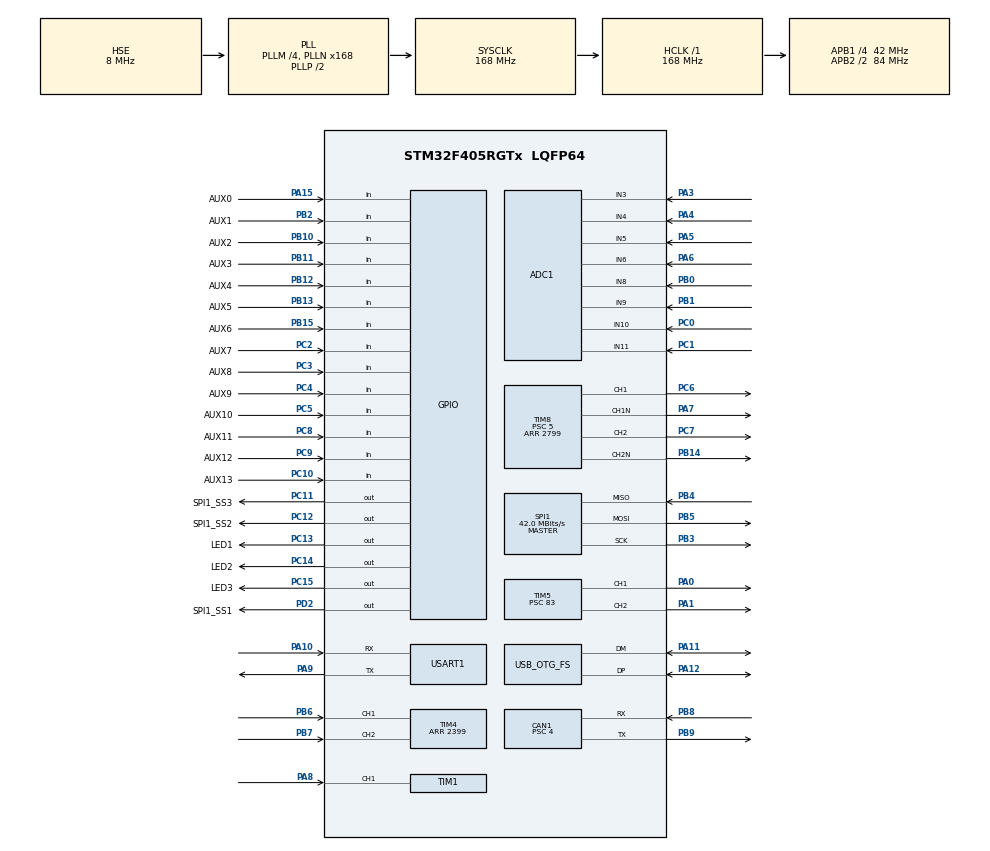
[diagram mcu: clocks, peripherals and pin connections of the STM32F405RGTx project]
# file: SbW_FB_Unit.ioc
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ADC1.Channel-0\#ChannelRegularConversion=ADC_CHANNEL_3
ADC1.Channel-10\#ChannelRegularConversion=ADC_CHANNEL_4
ADC1.Channel-3\#ChannelRegularConversion=ADC_CHANNEL_4
ADC1.Channel-4\#ChannelRegularConversion=ADC_CHANNEL_3
ADC1.Channel-5\#ChannelRegularConversion=ADC_CHANNEL_3
ADC1.Channel-6\#ChannelRegularConversion=ADC_CHANNEL_3
ADC1.Channel-7\#ChannelRegularConversion=ADC_CHANNEL_3
ADC1.Channel-8\#ChannelRegularConversion=ADC_CHANNEL_3
ADC1.Channel-9\#ChannelRegularConversion=ADC_CHANNEL_3
ADC1.DMAContinuousRequests=ENABLE
ADC1.EOCSelection=ADC_EOC_SEQ_CONV
ADC1.ExternalTrigConv=ADC_EXTERNALTRIGCONV_T5_CC2
ADC1.NbrOfConversion=9
ADC1.NbrOfConversionFlag=1
ADC1.Rank-0\#ChannelRegularConversion=1
ADC1.Rank-10\#ChannelRegularConversion=9
ADC1.Rank-3\#ChannelRegularConversion=2
ADC1.Rank-4\#ChannelRegularConversion=3
ADC1.Rank-5\#ChannelRegularConversion=4
ADC1.Rank-6\#ChannelRegularConversion=5
ADC1.Rank-7\#ChannelRegularConversion=6
ADC1.Rank-8\#ChannelRegularConversion=7
ADC1.Rank-9\#ChannelRegularConversion=8
ADC1.SamplingTime-0\#ChannelRegularConversion=ADC_SAMPLETIME_112CYCLES
ADC1.SamplingTime-10\#ChannelRegularConversion=ADC_SAMPLETIME_112CYCLES
ADC1.SamplingTime-3\#ChannelRegularConversion=ADC_SAMPLETIME_112CYCLES
ADC1.SamplingTime-4\#ChannelRegularConversion=ADC_SAMPLETIME_3CYCLES
ADC1.SamplingTime-5\#ChannelRegularConversion=ADC_SAMPLETIME_3CYCLES
ADC1.SamplingTime-6\#ChannelRegularConversion=ADC_SAMPLETIME_3CYCLES
ADC1.SamplingTime-7\#ChannelRegularConversion=ADC_SAMPLETIME_3CYCLES
ADC1.SamplingTime-8\#ChannelRegularConversion=ADC_SAMPLETIME_3CYCLES
ADC1.SamplingTime-9\#ChannelRegularConversion=ADC_SAMPLETIME_3CYCLES
ADC1.ScanConvMode=ENABLE
ADC1.master=1
CAN1.BS1=CAN_BS1_15TQ
CAN1.BS2=CAN_BS2_5TQ
CAN1.CalculateBaudRate=500000
CAN1.CalculateTimeBit=2000
CAN1.CalculateTimeQuantum=95.23809523809524
CAN1.Prescaler=4
Dma.ADC1.1.Direction=DMA_PERIPH_TO_MEMORY
Dma.ADC1.1.FIFOMode=DMA_FIFOMODE_DISABLE
Dma.ADC1.1.Instance=DMA2_Stream0
Dma.ADC1.1.MemDataAlignment=DMA_MDATAALIGN_HALFWORD
Dma.ADC1.1.MemInc=DMA_MINC_ENABLE
Dma.ADC1.1.Mode=DMA_CIRCULAR
Dma.ADC1.1.PeriphDataAlignment=DMA_PDATAALIGN_HALFWORD
Dma.ADC1.1.PeriphInc=DMA_PINC_DISABLE
Dma.ADC1.1.Priority=DMA_PRIORITY_LOW
Dma.Request0=USART1_TX
Dma.Request1=ADC1
Dma.Request2=USART1_RX
Dma.USART1_RX.2.Direction=DMA_PERIPH_TO_MEMORY
Dma.USART1_RX.2.FIFOMode=DMA_FIFOMODE_DISABLE
Dma.USART1_RX.2.Instance=DMA2_Stream2
Dma.USART1_RX.2.MemDataAlignment=DMA_MDATAALIGN_BYTE
Dma.USART1_RX.2.MemInc=DMA_MINC_ENABLE
Dma.USART1_RX.2.Mode=DMA_NORMAL
Dma.USART1_RX.2.PeriphDataAlignment=DMA_PDATAALIGN_BYTE
Dma.USART1_RX.2.PeriphInc=DMA_PINC_DISABLE
Dma.USART1_RX.2.Priority=DMA_PRIORITY_LOW
Dma.USART1_TX.0.Direction=DMA_MEMORY_TO_PERIPH
Dma.USART1_TX.0.FIFOMode=DMA_FIFOMODE_DISABLE
Dma.USART1_TX.0.Instance=DMA2_Stream7
Dma.USART1_TX.0.MemDataAlignment=DMA_MDATAALIGN_BYTE
Dma.USART1_TX.0.MemInc=DMA_MINC_ENABLE
Dma.USART1_TX.0.Mode=DMA_NORMAL
Dma.USART1_TX.0.PeriphDataAlignment=DMA_PDATAALIGN_BYTE
Dma.USART1_TX.0.PeriphInc=DMA_PINC_DISABLE
Dma.USART1_TX.0.Priority=DMA_PRIORITY_LOW
Mcu.Family=STM32F4
Mcu.Name=STM32F405RGTx
Mcu.Package=LQFP64
NVIC.ADC_IRQn=true\:0\:0\:false\:false\:true\:true\:true\:true
NVIC.CAN1_RX0_IRQn=true\:0\:0\:false\:false\:true\:true\:true\:true
NVIC.CAN1_RX1_IRQn=true\:0\:0\:false\:false\:true\:true\:true\:true
NVIC.CAN1_SCE_IRQn=true\:0\:0\:false\:false\:true\:true\:true\:true
NVIC.CAN1_TX_IRQn=true\:0\:0\:false\:false\:true\:true\:true\:true
NVIC.DMA2_Stream0_IRQn=true\:0\:0\:false\:false\:true\:false\:true\:true
NVIC.DMA2_Stream2_IRQn=true\:0\:0\:false\:false\:true\:false\:true\:true
NVIC.DMA2_Stream7_IRQn=true\:0\:0\:false\:false\:true\:false\:true\:true
NVIC.OTG_FS_IRQn=true\:0\:0\:false\:false\:true\:false\:true\:true
NVIC.PriorityGroup=NVIC_PRIORITYGROUP_4
NVIC.TIM4_IRQn=true\:0\:0\:false\:false\:true\:true\:true\:true
NVIC.TIM6_DAC_IRQn=true\:0\:0\:false\:false\:true\:true\:true\:true
NVIC.USART1_IRQn=true\:2\:0\:true\:false\:true\:true\:true\:true
PA0-WKUP.Signal=S_TIM5_CH1
PA1.Signal=S_TIM5_CH2
PA10.Mode=Asynchronous
PA10.Signal=USART1_RX
PA11.Mode=Device_Only
PA11.Signal=USB_OTG_FS_DM
PA12.Mode=Device_Only
PA12.Signal=USB_OTG_FS_DP
PA13.Mode=Serial_Wire
PA13.Signal=SYS_JTMS-SWDIO
PA14.Mode=Serial_Wire
PA14.Signal=SYS_JTCK-SWCLK
PA15.GPIO_Label=AUX0
PA15.Signal=GPIO_Input
PA3.Signal=ADCx_IN3
PA4.Signal=ADCx_IN4
PA5.Signal=ADCx_IN5
PA6.Signal=ADCx_IN6
PA7.Mode=PWM Generation1 CH1 CH1N
PA7.Signal=TIM8_CH1N
PA8.Signal=S_TIM1_CH1
PA9.Mode=Asynchronous
PA9.Signal=USART1_TX
PB0.Signal=ADCx_IN8
PB1.Signal=ADCx_IN9
PB10.GPIO_Label=AUX2
PB10.Signal=GPIO_Input
PB11.GPIO_Label=AUX3
PB11.Signal=GPIO_Input
PB12.GPIO_Label=AUX4
PB12.Signal=GPIO_Input
PB13.GPIO_Label=AUX5
PB13.Signal=GPIO_Input
PB14.Mode=PWM Generation2 CH2 CH2N
PB14.Signal=TIM8_CH2N
PB15.GPIO_Label=AUX6
PB15.Signal=GPIO_Input
PB2.GPIO_Label=AUX1
PB2.Signal=GPIO_Input
PB3.Mode=Full_Duplex_Master
PB3.Signal=SPI1_SCK
PB4.Mode=Full_Duplex_Master
PB4.Signal=SPI1_MISO
PB5.Mode=Full_Duplex_Master
PB5.Signal=SPI1_MOSI
PB6.Signal=S_TIM4_CH1
PB7.Signal=S_TIM4_CH2
PB8.Mode=CAN_Activate
PB8.Signal=CAN1_RX
PB9.Mode=CAN_Activate
PB9.Signal=CAN1_TX
PC0.Signal=ADCx_IN10
PC1.Signal=ADCx_IN11
PC10.GPIO_Label=AUX13
PC10.Signal=GPIO_Input
PC11.GPIO_Label=SPI1_SS3
PC11.Signal=GPIO_Output
PC12.GPIO_Label=SPI1_SS2
PC12.Signal=GPIO_Output
PC13-ANTI_TAMP.GPIO_Label=LED1
PC13-ANTI_TAMP.Signal=GPIO_Output
PC14-OSC32_IN.GPIO_Label=LED2
PC14-OSC32_IN.Signal=GPIO_Output
PC15-OSC32_OUT.GPIO_Label=LED3
PC15-OSC32_OUT.Signal=GPIO_Output
PC2.GPIO_Label=AUX7
PC2.Signal=GPIO_Input
PC3.GPIO_Label=AUX8
PC3.Signal=GPIO_Input
PC4.GPIO_Label=AUX9
PC4.Signal=GPIO_Input
PC5.GPIO_Label=AUX10
PC5.Signal=GPIO_Input
PC6.Signal=S_TIM8_CH1
PC7.Signal=S_TIM8_CH2
PC8.GPIO_Label=AUX11
PC8.Signal=GPIO_Input
PC9.GPIO_Label=AUX12
PC9.Signal=GPIO_Input
PD2.GPIO_Label=SPI1_SS1
PD2.Signal=GPIO_Output
PH0-OSC_IN.Mode=HSE-External-Oscillator
PH0-OSC_IN.Signal=RCC_OSC_IN
PH1-OSC_OUT.Mode=HSE-External-Oscillator
PH1-OSC_OUT.Signal=RCC_OSC_OUT
ProjectManager.HeapSize=0x200
ProjectManager.StackSize=0x400
ProjectManager.TargetToolchain=STM32CubeIDE
RCC.48MHZClocksFreq_Value=48000000
RCC.AHBFreq_Value=168000000
RCC.APB1CLKDivider=RCC_HCLK_DIV4
RCC.APB1Freq_Value=42000000
RCC.APB1TimFreq_Value=84000000
RCC.APB2CLKDivider=RCC_HCLK_DIV2
RCC.APB2Freq_Value=84000000
RCC.APB2TimFreq_Value=168000000
RCC.CortexFreq_Value=168000000
RCC.HCLKFreq_Value=168000000
RCC.HSE_VALUE=8000000
RCC.HSI_VALUE=16000000
RCC.LSE_VALUE=32768
RCC.PLLM=4
RCC.PLLN=168
RCC.PLLQ=7
RCC.SYSCLKFreq_VALUE=168000000
RCC.SYSCLKSource=RCC_SYSCLKSOURCE_PLLCLK
RCC.VCOOutputFreq_Value=336000000
SH.ADCx_IN10.0=ADC1_IN10,IN10
SH.ADCx_IN11.0=ADC1_IN11,IN11
SH.ADCx_IN3.0=ADC1_IN3,IN3
SH.ADCx_IN4.0=ADC1_IN4,IN4
SH.ADCx_IN5.0=ADC1_IN5,IN5
SH.ADCx_IN6.0=ADC1_IN6,IN6
SH.ADCx_IN8.0=ADC1_IN8,IN8
SH.ADCx_IN9.0=ADC1_IN9,IN9
SH.S_TIM1_CH1.0=TIM1_CH1,Input_Capture1_from_TI1
SH.S_TIM4_CH1.0=TIM4_CH1,Encoder_Interface
SH.S_TIM4_CH2.0=TIM4_CH2,Encoder_Interface
SH.S_TIM5_CH1.0=TIM5_CH1,PWM Generation1 CH1
SH.S_TIM5_CH2.0=TIM5_CH2,PWM Generation2 CH2
SH.S_TIM8_CH1.0=TIM8_CH1,PWM Generation1 CH1 CH1N
SH.S_TIM8_CH2.0=TIM8_CH2,PWM Generation2 CH2 CH2N
SPI1.CalculateBaudRate=42.0 MBits/s
SPI1.Direction=SPI_DIRECTION_2LINES
SPI1.Mode=SPI_MODE_MASTER
SPI1.VirtualType=VM_MASTER
TIM1.Channel-Input_Capture1_from_TI1=TIM_CHANNEL_1
TIM1.Period=1000
TIM1.Prescaler=167
TIM4.EncoderMode=TIM_ENCODERMODE_TI12
TIM4.Period=2399
TIM4.TIM_MasterOutputTrigger=TIM_TRGO_ENABLE
TIM5.Channel-PWM\ Generation1\ CH1=TIM_CHANNEL_1
TIM5.Channel-PWM\ Generation2\ CH2=TIM_CHANNEL_2
TIM5.Period=999
TIM5.Prescaler=83
TIM5.Pulse-PWM\ Generation2\ CH2=499
TIM5.TIM_MasterOutputTrigger=TIM_TRGO_UPDATE
TIM6.Period=4999
TIM6.Prescaler=83
TIM6.TIM_MasterOutputTrigger=TIM_TRGO_ENABLE
TIM8.Channel-PWM\ Generation1\ CH1\ CH1N=TIM_CHANNEL_1
TIM8.Channel-PWM\ Generation2\ CH2\ CH2N=TIM_CHANNEL_2
TIM8.DeadTime=100
TIM8.Period=2799
TIM8.Prescaler=5
USART1.VirtualMode=VM_ASYNC
USB_DEVICE.CLASS_NAME_FS=CDC
USB_DEVICE.VirtualMode-CDC_FS=Cdc
USB_DEVICE.VirtualModeFS=Cdc_FS
USB_OTG_FS.VirtualMode=Device_Only
VP_TIM1_VS_ClockSourceINT.Mode=Internal
VP_TIM5_VS_ClockSourceINT.Mode=Internal
VP_TIM6_VS_ClockSourceINT.Mode=Enable_Timer
VP_TIM8_VS_ClockSourceINT.Mode=Internal
VP_USB_DEVICE_VS_USB_DEVICE_CDC_FS.Mode=CDC_FS
board=custom

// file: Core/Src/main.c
/* USER CODE BEGIN Header */
/**
 ******************************************************************************
 * @file           : main.c
 * @brief          : Main program body
 ******************************************************************************
 * @attention
 *
 * Copyright (c) 2025 STMicroelectronics.
 * All rights reserved.
 *
 * This software is licensed under terms that can be found in the LICENSE file
 * in the root directory of this software component.
 * If no LICENSE file comes with this software, it is provided AS-IS.
 *
 ******************************************************************************
 */
/* USER CODE END Header */
#include "main.h"
#include "usb_device.h"

/* USER CODE BEGIN Includes */
#include "Application.h"
/* USER CODE END Includes */

ADC_HandleTypeDef hadc1;
DMA_HandleTypeDef hdma_adc1;

CAN_HandleTypeDef hcan1;

SPI_HandleTypeDef hspi1;

TIM_HandleTypeDef htim1;
TIM_HandleTypeDef htim4;
TIM_HandleTypeDef htim5;
TIM_HandleTypeDef htim6;
TIM_HandleTypeDef htim8;

UART_HandleTypeDef huart1;
DMA_HandleTypeDef hdma_usart1_tx;
DMA_HandleTypeDef hdma_usart1_rx;

void SystemClock_Config(void);
static void MX_GPIO_Init(void);
static void MX_DMA_Init(void);
static void MX_ADC1_Init(void);
static void MX_SPI1_Init(void);
static void MX_TIM1_Init(void);
static void MX_TIM5_Init(void);
static void MX_TIM8_Init(void);
static void MX_USART1_UART_Init(void);
static void MX_TIM6_Init(void);
static void MX_TIM4_Init(void);
static void MX_CAN1_Init(void);

int main(void)
{

  /* MCU Configuration--------------------------------------------------------*/

  /* Reset of all peripherals, Initializes the Flash interface and the Systick. */
  HAL_Init();

  /* Configure the system clock */
  SystemClock_Config();

  /* Initialize all configured peripherals */
  MX_GPIO_Init();
  MX_DMA_Init();
  MX_ADC1_Init();
  MX_SPI1_Init();
  MX_TIM1_Init();
  MX_TIM5_Init();
  MX_TIM8_Init();
  MX_USART1_UART_Init();
  MX_USB_DEVICE_Init();
  MX_TIM6_Init();
  MX_TIM4_Init();
  MX_CAN1_Init();
  /* USER CODE BEGIN 2 */
	Application_Init();
	Application_Run();
  /* USER CODE END 2 */

  /* Infinite loop */
	while (1)
	{

	}
}

void SystemClock_Config(void)
{
  RCC_OscInitTypeDef RCC_OscInitStruct = {0};
  RCC_ClkInitTypeDef RCC_ClkInitStruct = {0};

  /** Configure the main internal regulator output voltage
  */
  __HAL_RCC_PWR_CLK_ENABLE();
  __HAL_PWR_VOLTAGESCALING_CONFIG(PWR_REGULATOR_VOLTAGE_SCALE1);

  /** Initializes the RCC Oscillators according to the specified parameters
  * in the RCC_OscInitTypeDef structure.
  */
  RCC_OscInitStruct.OscillatorType = RCC_OSCILLATORTYPE_HSE;
  RCC_OscInitStruct.HSEState = RCC_HSE_ON;
  RCC_OscInitStruct.PLL.PLLState = RCC_PLL_ON;
  RCC_OscInitStruct.PLL.PLLSource = RCC_PLLSOURCE_HSE;
  RCC_OscInitStruct.PLL.PLLM = 4;
  RCC_OscInitStruct.PLL.PLLN = 168;
  RCC_OscInitStruct.PLL.PLLP = RCC_PLLP_DIV2;
  RCC_OscInitStruct.PLL.PLLQ = 7;
  if (HAL_RCC_OscConfig(&RCC_OscInitStruct) != HAL_OK)
  {
    Error_Handler();
  }

  /** Initializes the CPU, AHB and APB buses clocks
  */
  RCC_ClkInitStruct.ClockType = RCC_CLOCKTYPE_HCLK|RCC_CLOCKTYPE_SYSCLK
                              |RCC_CLOCKTYPE_PCLK1|RCC_CLOCKTYPE_PCLK2;
  RCC_ClkInitStruct.SYSCLKSource = RCC_SYSCLKSOURCE_PLLCLK;
  RCC_ClkInitStruct.AHBCLKDivider = RCC_SYSCLK_DIV1;
  RCC_ClkInitStruct.APB1CLKDivider = RCC_HCLK_DIV4;
  RCC_ClkInitStruct.APB2CLKDivider = RCC_HCLK_DIV2;

  if (HAL_RCC_ClockConfig(&RCC_ClkInitStruct, FLASH_LATENCY_5) != HAL_OK)
  {
    Error_Handler();
  }
}

static void MX_ADC1_Init(void)
{

  ADC_ChannelConfTypeDef sConfig = {0};

  /** Configure the global features of the ADC (Clock, Resolution, Data Alignment and number of conversion)
  */
  hadc1.Instance = ADC1;
  hadc1.Init.ClockPrescaler = ADC_CLOCK_SYNC_PCLK_DIV4;
  hadc1.Init.Resolution = ADC_RESOLUTION_12B;
  hadc1.Init.ScanConvMode = ENABLE;
  hadc1.Init.ContinuousConvMode = DISABLE;
  hadc1.Init.DiscontinuousConvMode = DISABLE;
  hadc1.Init.ExternalTrigConvEdge = ADC_EXTERNALTRIGCONVEDGE_RISING;
  hadc1.Init.ExternalTrigConv = ADC_EXTERNALTRIGCONV_T5_CC2;
  hadc1.Init.DataAlign = ADC_DATAALIGN_RIGHT;
  hadc1.Init.NbrOfConversion = 9;
  hadc1.Init.DMAContinuousRequests = ENABLE;
  hadc1.Init.EOCSelection = ADC_EOC_SEQ_CONV;
  if (HAL_ADC_Init(&hadc1) != HAL_OK)
  {
    Error_Handler();
  }

  /** Configure for the selected ADC regular channel its corresponding rank in the sequencer and its sample time.
  */
  sConfig.Channel = ADC_CHANNEL_3;
  sConfig.Rank = 1;
  sConfig.SamplingTime = ADC_SAMPLETIME_112CYCLES;
  if (HAL_ADC_ConfigChannel(&hadc1, &sConfig) != HAL_OK)
  {
    Error_Handler();
  }

  /** Configure for the selected ADC regular channel its corresponding rank in the sequencer and its sample time.
  */
  sConfig.Channel = ADC_CHANNEL_4;
  sConfig.Rank = 2;
  if (HAL_ADC_ConfigChannel(&hadc1, &sConfig) != HAL_OK)
  {
    Error_Handler();
  }

  /** Configure for the selected ADC regular channel its corresponding rank in the sequencer and its sample time.
  */
  sConfig.Channel = ADC_CHANNEL_3;
  sConfig.Rank = 3;
  sConfig.SamplingTime = ADC_SAMPLETIME_3CYCLES;
  if (HAL_ADC_ConfigChannel(&hadc1, &sConfig) != HAL_OK)
  {
    Error_Handler();
  }

  /** Configure for the selected ADC regular channel its corresponding rank in the sequencer and its sample time.
  */
  sConfig.Rank = 4;
  if (HAL_ADC_ConfigChannel(&hadc1, &sConfig) != HAL_OK)
  {
    Error_Handler();
  }

  /** Configure for the selected ADC regular channel its corresponding rank in the sequencer and its sample time.
  */
  sConfig.Rank = 5;
  if (HAL_ADC_ConfigChannel(&hadc1, &sConfig) != HAL_OK)
  {
    Error_Handler();
  }

  /** Configure for the selected ADC regular channel its corresponding rank in the sequencer and its sample time.
  */
  sConfig.Rank = 6;
  if (HAL_ADC_ConfigChannel(&hadc1, &sConfig) != HAL_OK)
  {
    Error_Handler();
  }

  /** Configure for the selected ADC regular channel its corresponding rank in the sequencer and its sample time.
  */
  sConfig.Rank = 7;
  if (HAL_ADC_ConfigChannel(&hadc1, &sConfig) != HAL_OK)
  {
    Error_Handler();
  }

  /** Configure for the selected ADC regular channel its corresponding rank in the sequencer and its sample time.
  */
  sConfig.Rank = 8;
  if (HAL_ADC_ConfigChannel(&hadc1, &sConfig) != HAL_OK)
  {
    Error_Handler();
  }

  /** Configure for the selected ADC regular channel its corresponding rank in the sequencer and its sample time.
  */
  sConfig.Channel = ADC_CHANNEL_4;
  sConfig.Rank = 9;
  sConfig.SamplingTime = ADC_SAMPLETIME_112CYCLES;
  if (HAL_ADC_ConfigChannel(&hadc1, &sConfig) != HAL_OK)
  {
    Error_Handler();
  }

}

static void MX_CAN1_Init(void)
{

  hcan1.Instance = CAN1;
  hcan1.Init.Prescaler = 4;
  hcan1.Init.Mode = CAN_MODE_NORMAL;
  hcan1.Init.SyncJumpWidth = CAN_SJW_1TQ;
  hcan1.Init.TimeSeg1 = CAN_BS1_15TQ;
  hcan1.Init.TimeSeg2 = CAN_BS2_5TQ;
  hcan1.Init.TimeTriggeredMode = DISABLE;
  hcan1.Init.AutoBusOff = DISABLE;
  hcan1.Init.AutoWakeUp = DISABLE;
  hcan1.Init.AutoRetransmission = DISABLE;
  hcan1.Init.ReceiveFifoLocked = DISABLE;
  hcan1.Init.TransmitFifoPriority = DISABLE;
  if (HAL_CAN_Init(&hcan1) != HAL_OK)
  {
    Error_Handler();
  }

}

static void MX_SPI1_Init(void)
{

  /* SPI1 parameter configuration*/
  hspi1.Instance = SPI1;
  hspi1.Init.Mode = SPI_MODE_MASTER;
  hspi1.Init.Direction = SPI_DIRECTION_2LINES;
  hspi1.Init.DataSize = SPI_DATASIZE_8BIT;
  hspi1.Init.CLKPolarity = SPI_POLARITY_LOW;
  hspi1.Init.CLKPhase = SPI_PHASE_1EDGE;
  hspi1.Init.NSS = SPI_NSS_SOFT;
  hspi1.Init.BaudRatePrescaler = SPI_BAUDRATEPRESCALER_2;
  hspi1.Init.FirstBit = SPI_FIRSTBIT_MSB;
  hspi1.Init.TIMode = SPI_TIMODE_DISABLE;
  hspi1.Init.CRCCalculation = SPI_CRCCALCULATION_DISABLE;
  hspi1.Init.CRCPolynomial = 10;
  if (HAL_SPI_Init(&hspi1) != HAL_OK)
  {
    Error_Handler();
  }

}

static void MX_TIM1_Init(void)
{

  TIM_ClockConfigTypeDef sClockSourceConfig = {0};
  TIM_MasterConfigTypeDef sMasterConfig = {0};

  htim1.Instance = TIM1;
  htim1.Init.Prescaler = 83;
  htim1.Init.CounterMode = TIM_COUNTERMODE_UP;
  htim1.Init.Period = 1000;
  htim1.Init.ClockDivision = TIM_CLOCKDIVISION_DIV1;
  htim1.Init.RepetitionCounter = 0;
  htim1.Init.AutoReloadPreload = TIM_AUTORELOAD_PRELOAD_DISABLE;
  if (HAL_TIM_Base_Init(&htim1) != HAL_OK)
  {
    Error_Handler();
  }
  sClockSourceConfig.ClockSource = TIM_CLOCKSOURCE_INTERNAL;
  if (HAL_TIM_ConfigClockSource(&htim1, &sClockSourceConfig) != HAL_OK)
  {
    Error_Handler();
  }
  sMasterConfig.MasterOutputTrigger = TIM_TRGO_RESET;
  sMasterConfig.MasterSlaveMode = TIM_MASTERSLAVEMODE_DISABLE;
  if (HAL_TIMEx_MasterConfigSynchronization(&htim1, &sMasterConfig) != HAL_OK)
  {
    Error_Handler();
  }

}

static void MX_TIM4_Init(void)
{

  TIM_Encoder_InitTypeDef sConfig = {0};
  TIM_MasterConfigTypeDef sMasterConfig = {0};

  htim4.Instance = TIM4;
  htim4.Init.Prescaler = 0;
  htim4.Init.CounterMode = TIM_COUNTERMODE_UP;
  htim4.Init.Period = 2399;
  htim4.Init.ClockDivision = TIM_CLOCKDIVISION_DIV1;
  htim4.Init.AutoReloadPreload = TIM_AUTORELOAD_PRELOAD_DISABLE;
  sConfig.EncoderMode = TIM_ENCODERMODE_TI12;
  sConfig.IC1Polarity = TIM_ICPOLARITY_RISING;
  sConfig.IC1Selection = TIM_ICSELECTION_DIRECTTI;
  sConfig.IC1Prescaler = TIM_ICPSC_DIV1;
  sConfig.IC1Filter = 0;
  sConfig.IC2Polarity = TIM_ICPOLARITY_RISING;
  sConfig.IC2Selection = TIM_ICSELECTION_DIRECTTI;
  sConfig.IC2Prescaler = TIM_ICPSC_DIV1;
  sConfig.IC2Filter = 0;
  if (HAL_TIM_Encoder_Init(&htim4, &sConfig) != HAL_OK)
  {
    Error_Handler();
  }
  sMasterConfig.MasterOutputTrigger = TIM_TRGO_ENABLE;
  sMasterConfig.MasterSlaveMode = TIM_MASTERSLAVEMODE_DISABLE;
  if (HAL_TIMEx_MasterConfigSynchronization(&htim4, &sMasterConfig) != HAL_OK)
  {
    Error_Handler();
  }

}

static void MX_TIM5_Init(void)
{

  TIM_ClockConfigTypeDef sClockSourceConfig = {0};
  TIM_MasterConfigTypeDef sMasterConfig = {0};
  TIM_OC_InitTypeDef sConfigOC = {0};

  htim5.Instance = TIM5;
  htim5.Init.Prescaler = 83;
  htim5.Init.CounterMode = TIM_COUNTERMODE_UP;
  htim5.Init.Period = 999;
  htim5.Init.ClockDivision = TIM_CLOCKDIVISION_DIV1;
  htim5.Init.AutoReloadPreload = TIM_AUTORELOAD_PRELOAD_DISABLE;
  if (HAL_TIM_Base_Init(&htim5) != HAL_OK)
  {
    Error_Handler();
  }
  sClockSourceConfig.ClockSource = TIM_CLOCKSOURCE_INTERNAL;
  if (HAL_TIM_ConfigClockSource(&htim5, &sClockSourceConfig) != HAL_OK)
  {
    Error_Handler();
  }
  if (HAL_TIM_PWM_Init(&htim5) != HAL_OK)
  {
    Error_Handler();
  }
  sMasterConfig.MasterOutputTrigger = TIM_TRGO_UPDATE;
  sMasterConfig.MasterSlaveMode = TIM_MASTERSLAVEMODE_DISABLE;
  if (HAL_TIMEx_MasterConfigSynchronization(&htim5, &sMasterConfig) != HAL_OK)
  {
    Error_Handler();
  }
  sConfigOC.OCMode = TIM_OCMODE_PWM1;
  sConfigOC.Pulse = 0;
  sConfigOC.OCPolarity = TIM_OCPOLARITY_HIGH;
  sConfigOC.OCFastMode = TIM_OCFAST_DISABLE;
  if (HAL_TIM_PWM_ConfigChannel(&htim5, &sConfigOC, TIM_CHANNEL_1) != HAL_OK)
  {
    Error_Handler();
  }
  sConfigOC.Pulse = 499;
  if (HAL_TIM_PWM_ConfigChannel(&htim5, &sConfigOC, TIM_CHANNEL_2) != HAL_OK)
  {
    Error_Handler();
  }
  HAL_TIM_MspPostInit(&htim5);

}

static void MX_TIM6_Init(void)
{

  TIM_MasterConfigTypeDef sMasterConfig = {0};

  htim6.Instance = TIM6;
  htim6.Init.Prescaler = 83;
  htim6.Init.CounterMode = TIM_COUNTERMODE_UP;
  htim6.Init.Period = 4999;
  htim6.Init.AutoReloadPreload = TIM_AUTORELOAD_PRELOAD_DISABLE;
  if (HAL_TIM_Base_Init(&htim6) != HAL_OK)
  {
    Error_Handler();
  }
  sMasterConfig.MasterOutputTrigger = TIM_TRGO_ENABLE;
  sMasterConfig.MasterSlaveMode = TIM_MASTERSLAVEMODE_DISABLE;
  if (HAL_TIMEx_MasterConfigSynchronization(&htim6, &sMasterConfig) != HAL_OK)
  {
    Error_Handler();
  }

}

static void MX_TIM8_Init(void)
{

  TIM_ClockConfigTypeDef sClockSourceConfig = {0};
  TIM_MasterConfigTypeDef sMasterConfig = {0};
  TIM_OC_InitTypeDef sConfigOC = {0};
  TIM_BreakDeadTimeConfigTypeDef sBreakDeadTimeConfig = {0};

  htim8.Instance = TIM8;
  htim8.Init.Prescaler = 5;
  htim8.Init.CounterMode = TIM_COUNTERMODE_UP;
  htim8.Init.Period = 2799;
  htim8.Init.ClockDivision = TIM_CLOCKDIVISION_DIV1;
  htim8.Init.RepetitionCounter = 0;
  htim8.Init.AutoReloadPreload = TIM_AUTORELOAD_PRELOAD_DISABLE;
  if (HAL_TIM_Base_Init(&htim8) != HAL_OK)
  {
    Error_Handler();
  }
  sClockSourceConfig.ClockSource = TIM_CLOCKSOURCE_INTERNAL;
  if (HAL_TIM_ConfigClockSource(&htim8, &sClockSourceConfig) != HAL_OK)
  {
    Error_Handler();
  }
  if (HAL_TIM_PWM_Init(&htim8) != HAL_OK)
  {
    Error_Handler();
  }
  sMasterConfig.MasterOutputTrigger = TIM_TRGO_RESET;
  sMasterConfig.MasterSlaveMode = TIM_MASTERSLAVEMODE_DISABLE;
  if (HAL_TIMEx_MasterConfigSynchronization(&htim8, &sMasterConfig) != HAL_OK)
  {
    Error_Handler();
  }
  sConfigOC.OCMode = TIM_OCMODE_PWM1;
  sConfigOC.Pulse = 0;
  sConfigOC.OCPolarity = TIM_OCPOLARITY_HIGH;
  sConfigOC.OCNPolarity = TIM_OCNPOLARITY_HIGH;
  sConfigOC.OCFastMode = TIM_OCFAST_DISABLE;
  sConfigOC.OCIdleState = TIM_OCIDLESTATE_RESET;
  sConfigOC.OCNIdleState = TIM_OCNIDLESTATE_RESET;
  if (HAL_TIM_PWM_ConfigChannel(&htim8, &sConfigOC, TIM_CHANNEL_1) != HAL_OK)
  {
    Error_Handler();
  }
  if (HAL_TIM_PWM_ConfigChannel(&htim8, &sConfigOC, TIM_CHANNEL_2) != HAL_OK)
  {
    Error_Handler();
  }
  sBreakDeadTimeConfig.OffStateRunMode = TIM_OSSR_DISABLE;
  sBreakDeadTimeConfig.OffStateIDLEMode = TIM_OSSI_DISABLE;
  sBreakDeadTimeConfig.LockLevel = TIM_LOCKLEVEL_OFF;
  sBreakDeadTimeConfig.DeadTime = 100;
  sBreakDeadTimeConfig.BreakState = TIM_BREAK_DISABLE;
  sBreakDeadTimeConfig.BreakPolarity = TIM_BREAKPOLARITY_HIGH;
  sBreakDeadTimeConfig.AutomaticOutput = TIM_AUTOMATICOUTPUT_DISABLE;
  if (HAL_TIMEx_ConfigBreakDeadTime(&htim8, &sBreakDeadTimeConfig) != HAL_OK)
  {
    Error_Handler();
  }
  HAL_TIM_MspPostInit(&htim8);

}

static void MX_USART1_UART_Init(void)
{

  huart1.Instance = USART1;
  huart1.Init.BaudRate = 115200;
  huart1.Init.WordLength = UART_WORDLENGTH_8B;
  huart1.Init.StopBits = UART_STOPBITS_1;
  huart1.Init.Parity = UART_PARITY_NONE;
  huart1.Init.Mode = UART_MODE_TX_RX;
  huart1.Init.HwFlowCtl = UART_HWCONTROL_NONE;
  huart1.Init.OverSampling = UART_OVERSAMPLING_16;
  if (HAL_UART_Init(&huart1) != HAL_OK)
  {
    Error_Handler();
  }

}

static void MX_DMA_Init(void)
{

  /* DMA controller clock enable */
  __HAL_RCC_DMA2_CLK_ENABLE();

  /* DMA interrupt init */
  /* DMA2_Stream0_IRQn interrupt configuration */
  HAL_NVIC_SetPriority(DMA2_Stream0_IRQn, 0, 0);
  HAL_NVIC_EnableIRQ(DMA2_Stream0_IRQn);
  /* DMA2_Stream2_IRQn interrupt configuration */
  HAL_NVIC_SetPriority(DMA2_Stream2_IRQn, 0, 0);
  HAL_NVIC_EnableIRQ(DMA2_Stream2_IRQn);
  /* DMA2_Stream7_IRQn interrupt configuration */
  HAL_NVIC_SetPriority(DMA2_Stream7_IRQn, 0, 0);
  HAL_NVIC_EnableIRQ(DMA2_Stream7_IRQn);

}

static void MX_GPIO_Init(void)
{
  GPIO_InitTypeDef GPIO_InitStruct = {0};

  /* GPIO Ports Clock Enable */
  __HAL_RCC_GPIOC_CLK_ENABLE();
  __HAL_RCC_GPIOH_CLK_ENABLE();
  __HAL_RCC_GPIOA_CLK_ENABLE();
  __HAL_RCC_GPIOB_CLK_ENABLE();
  __HAL_RCC_GPIOD_CLK_ENABLE();

  /*Configure GPIO pin Output Level */
  HAL_GPIO_WritePin(GPIOC, LED1_Pin|LED2_Pin|LED3_Pin|SPI1_SS3_Pin
                          |SPI1_SS2_Pin, GPIO_PIN_RESET);

  /*Configure GPIO pin Output Level */
  HAL_GPIO_WritePin(SPI1_SS1_GPIO_Port, SPI1_SS1_Pin, GPIO_PIN_RESET);

  /*Configure GPIO pins : LED1_Pin LED2_Pin LED3_Pin SPI1_SS3_Pin
                           SPI1_SS2_Pin */
  GPIO_InitStruct.Pin = LED1_Pin|LED2_Pin|LED3_Pin|SPI1_SS3_Pin
                          |SPI1_SS2_Pin;
  GPIO_InitStruct.Mode = GPIO_MODE_OUTPUT_PP;
  GPIO_InitStruct.Pull = GPIO_NOPULL;
  GPIO_InitStruct.Speed = GPIO_SPEED_FREQ_LOW;
  HAL_GPIO_Init(GPIOC, &GPIO_InitStruct);

  /*Configure GPIO pins : AUX7_Pin AUX8_Pin AUX9_Pin AUX10_Pin
                           AUX11_Pin AUX12_Pin AUX13_Pin */
  GPIO_InitStruct.Pin = AUX7_Pin|AUX8_Pin|AUX9_Pin|AUX10_Pin
                          |AUX11_Pin|AUX12_Pin|AUX13_Pin;
  GPIO_InitStruct.Mode = GPIO_MODE_INPUT;
  GPIO_InitStruct.Pull = GPIO_NOPULL;
  HAL_GPIO_Init(GPIOC, &GPIO_InitStruct);

  /*Configure GPIO pins : AUX1_Pin AUX2_Pin AUX3_Pin AUX4_Pin
                           AUX5_Pin AUX6_Pin */
  GPIO_InitStruct.Pin = AUX1_Pin|AUX2_Pin|AUX3_Pin|AUX4_Pin
                          |AUX5_Pin|AUX6_Pin;
  GPIO_InitStruct.Mode = GPIO_MODE_INPUT;
  GPIO_InitStruct.Pull = GPIO_NOPULL;
  HAL_GPIO_Init(GPIOB, &GPIO_InitStruct);

  /*Configure GPIO pin : AUX0_Pin */
  GPIO_InitStruct.Pin = AUX0_Pin;
  GPIO_InitStruct.Mode = GPIO_MODE_INPUT;
  GPIO_InitStruct.Pull = GPIO_NOPULL;
  HAL_GPIO_Init(AUX0_GPIO_Port, &GPIO_InitStruct);

  /*Configure GPIO pin : SPI1_SS1_Pin */
  GPIO_InitStruct.Pin = SPI1_SS1_Pin;
  GPIO_InitStruct.Mode = GPIO_MODE_OUTPUT_PP;
  GPIO_InitStruct.Pull = GPIO_NOPULL;
  GPIO_InitStruct.Speed = GPIO_SPEED_FREQ_LOW;
  HAL_GPIO_Init(SPI1_SS1_GPIO_Port, &GPIO_InitStruct);

}

void Error_Handler(void)
{
	__disable_irq();
	while (1)
	{
	}
}
